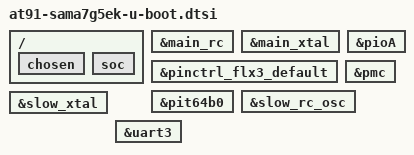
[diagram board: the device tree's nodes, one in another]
// SPDX-License-Identifier: (GPL-2.0+ OR MIT)
/*
 *  at91-sama7g5ek-u-boot.dtsi - Device Tree file for SAMA7G5 SoC u-boot
 *  properties.
 *
 *  Copyright (c) 2020 Microchip Technology Inc. and its subsidiaries
 *
 *  Author: Eugen Hristev <eugen.hristev@microchip.com>
 *  Author: Claudiu Beznea <claudiu.beznea@microchip.com>
 *
 */

/ {
	chosen {
		u-boot,dm-all;
	};

	soc {
		u-boot,dm-all;
	};
};

&main_rc {
	u-boot,dm-all;
};

&main_xtal {
	u-boot,dm-all;
};

&pioA {
	u-boot,dm-all;
};

&pinctrl_flx3_default {
	u-boot,dm-all;
};

&pioA {
	u-boot,dm-all;
};

&pit64b0 {
	u-boot,dm-all;
};

&pmc {
	u-boot,dm-all;
};

&slow_rc_osc {
	u-boot,dm-all;
};

&slow_xtal {
	u-boot,dm-all;
};

&uart3 {
	u-boot,dm-all;
};

